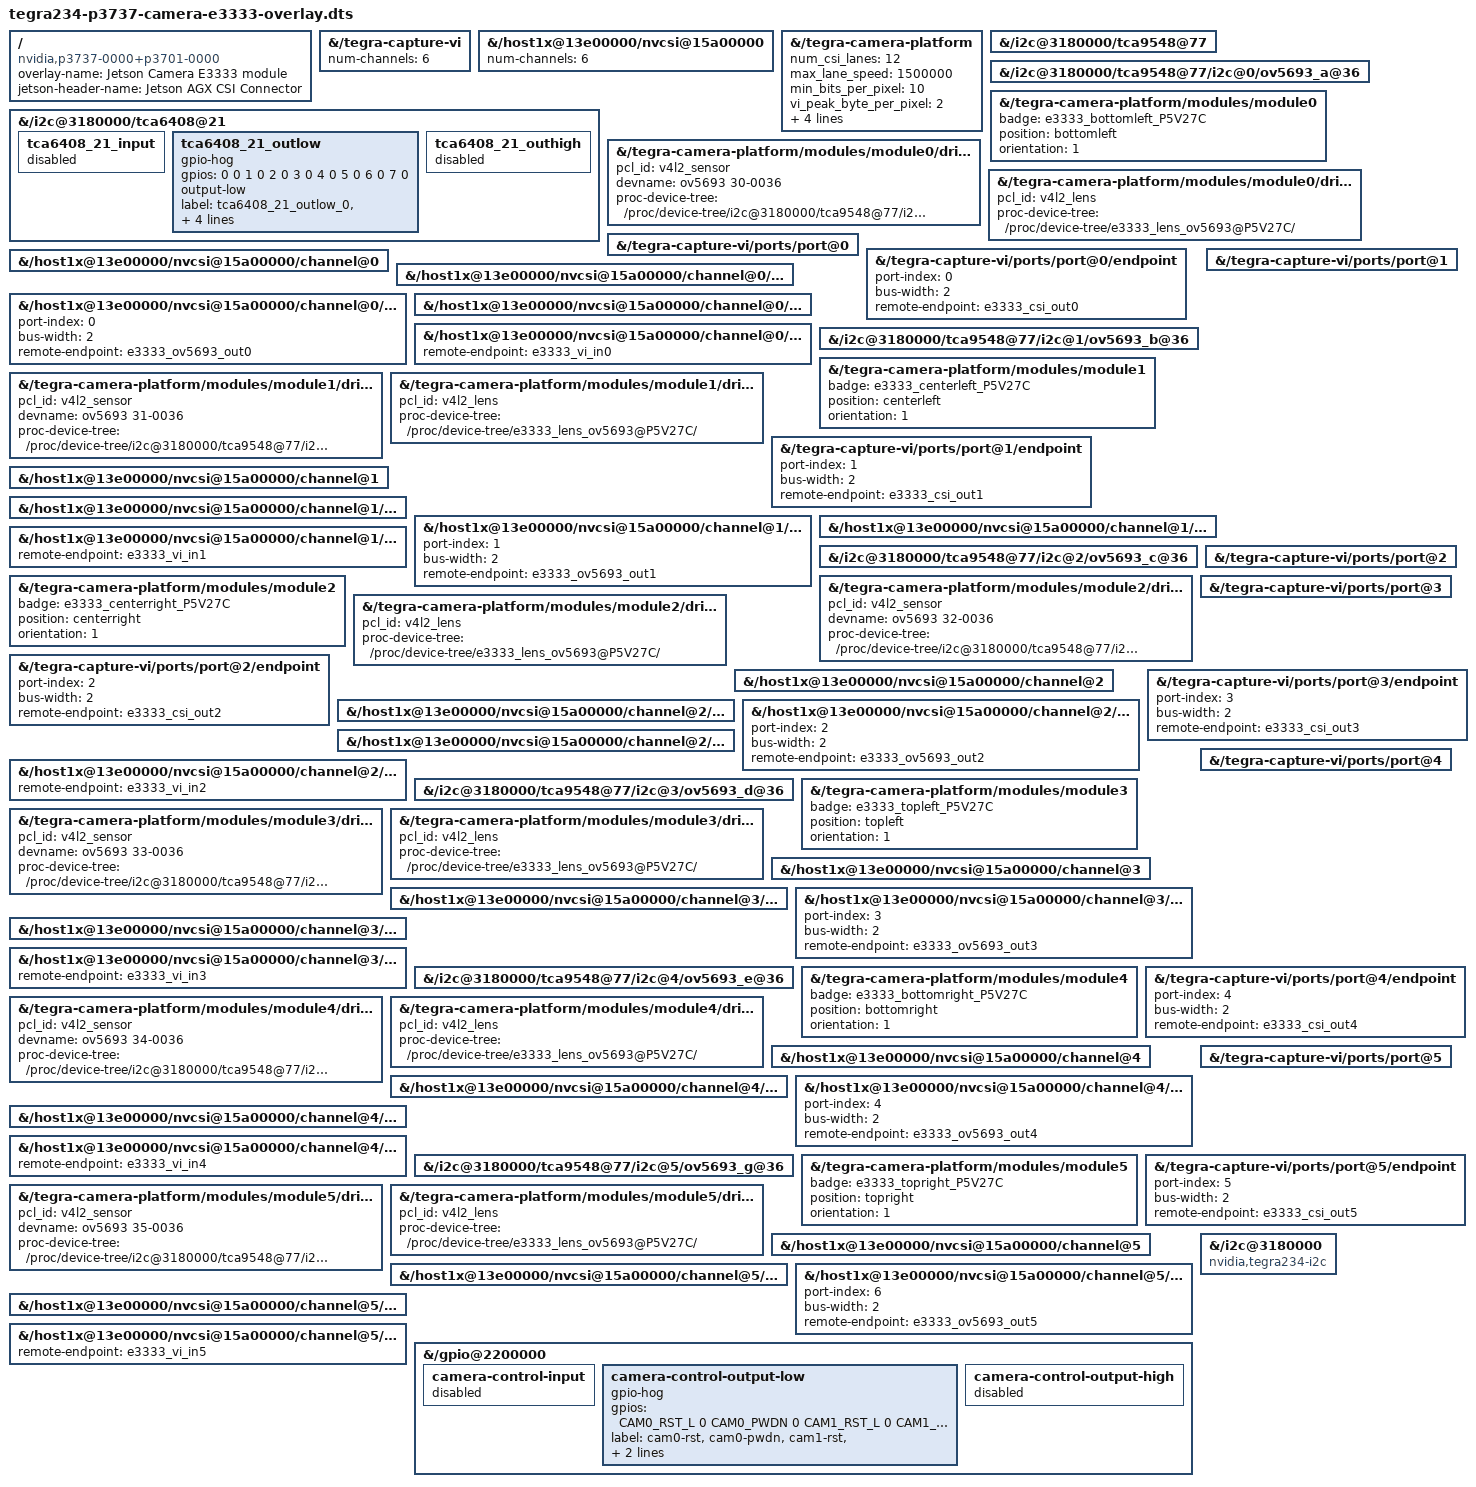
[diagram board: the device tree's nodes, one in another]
// SPDX-License-Identifier: GPL-2.0-only
/*
 * Jetson Device-tree overlay for Camera E3333 module on t23x platforms
 *
 * Copyright (c) 2022-2023 NVIDIA CORPORATION. All rights reserved.
 *
 */


/dts-v1/;
/plugin/;

#include <dt-bindings/gpio/tegra234-gpio.h>

#define CAM0_RST_L      TEGRA234_MAIN_GPIO(H, 3)
#define CAM0_PWDN       TEGRA234_MAIN_GPIO(H, 6)
#define CAM1_RST_L      TEGRA234_MAIN_GPIO(AC, 1)
#define CAM1_PWDN       TEGRA234_MAIN_GPIO(AC, 0)

/ {
	overlay-name = "Jetson Camera E3333 module";
	jetson-header-name = "Jetson AGX CSI Connector";
	compatible = "nvidia,p3737-0000+p3701-0000" , "nvidia,p3737-0000+p3701-0004", "nvidia,p3737-0000+p3701-0005", "nvidia,p3737-0000+p3701-0008";

	/* Use either odm-data or eeprom-ids for sensor detection */

	/* E3333 camera board */
	/* VI number of channels */
	fragment@0 {
		/// target = <&capture_vi_base>;
		target-path = "/tegra-capture-vi";
		board_config {
			// odm-data = "enable-3333-ov5693";
			ids = "3333-*";
			sw-modules = "kernel";
		};
		__overlay__ {
			num-channels=<6>;
		};
	};
	/* CSI number of channels */
	fragment@1 {
		/// target = <&csi_base>;
		target-path = "/host1x@13e00000/nvcsi@15a00000";
		board_config {
			// odm-data = "enable-3333-ov5693";
			ids = "3333-*";
			sw-modules = "kernel";
		};
		__overlay__ {
			num-channels=<6>;
		};
	};
	/* tegra-camera-platform settings */
	fragment@2 {
		/// target = <&tcp>;
		target-path = "/tegra-camera-platform";
		board_config {
			// odm-data = "enable-3333-ov5693";
			ids = "3333-*";
			sw-modules = "kernel";
		};
		__overlay__ {
			num_csi_lanes = <12>;
			max_lane_speed = <1500000>;
			min_bits_per_pixel = <10>;
			vi_peak_byte_per_pixel = <2>;
			vi_bw_margin_pct = <25>;
			max_pixel_rate = <200000>;
			isp_peak_byte_per_pixel = <5>;
			isp_bw_margin_pct = <25>;
		};
	};
	/* TCA6408 */
	fragment@3 {
		/// target = <&tca6408_21>;
		target-path = "/i2c@3180000/tca6408@21";
		board_config {
			// odm-data = "enable-3333-ov5693";
			ids = "3333-*";
			sw-modules = "kernel";
		};
		__overlay__ {
			status = "okay";
		};
	};
	/* TCA9548 */
	fragment@4 {
		/// target = <&tca9548_77>;
		target-path = "/i2c@3180000/tca9548@77";
		board_config {
			// odm-data = "enable-3333-ov5693";
			ids = "3333-*";
			sw-modules = "kernel";
		};
		__overlay__ {
			status = "okay";
		};
	};
	/* Camera 0: Module */
	fragment@5 {
		/// target = <&e3333_cam0>;
		target-path = "/i2c@3180000/tca9548@77/i2c@0/ov5693_a@36";
		board_config {
			// odm-data = "enable-3333-ov5693";
			ids = "3333-*";
			sw-modules = "kernel";
		};
		__overlay__ {
			status = "okay";
		};
	};
	fragment@6 {
		/// target = <&cam_module0>;
		target-path = "/tegra-camera-platform/modules/module0";
		board_config {
			// odm-data = "enable-3333-ov5693";
			ids = "3333-*";
			sw-modules = "kernel";
		};
		__overlay__ {
			status = "okay";
			badge = "e3333_bottomleft_P5V27C";
			position = "bottomleft";
			orientation = "1";
		};
	};
	fragment@7 {
		/// target = <&cam_module0_drivernode0>;
		target-path = "/tegra-camera-platform/modules/module0/drivernode0";
		board_config {
			// odm-data = "enable-3333-ov5693";
			ids = "3333-*";
			sw-modules = "kernel";
		};
		__overlay__ {
			status = "okay";
			pcl_id = "v4l2_sensor";
			devname = "ov5693 30-0036";
			proc-device-tree = "/proc/device-tree/i2c@3180000/tca9548@77/i2c@0/ov5693_a@36";
		};
	};
	fragment@8 {
		/// target = <&cam_module0_drivernode1>;
		target-path = "/tegra-camera-platform/modules/module0/drivernode1";
		board_config {
			// odm-data = "enable-3333-ov5693";
			ids = "3333-*";
			sw-modules = "kernel";
		};
		__overlay__ {
			status = "okay";
			pcl_id = "v4l2_lens";
			proc-device-tree = "/proc/device-tree/e3333_lens_ov5693@P5V27C/";
		};
	};
	/* Camera 0: VI */
	fragment@9 {
		/// target = <&vi_port0>;
		target-path = "/tegra-capture-vi/ports/port@0";
		board_config {
			// odm-data = "enable-3333-ov5693";
			ids = "3333-*";
			sw-modules = "kernel";
		};
		__overlay__ {
			status = "okay";
		};
	};
	fragment@10 {
		/// target = <&e3333_vi_in0>;
		target-path = "/tegra-capture-vi/ports/port@0/endpoint";
		board_config {
			// odm-data = "enable-3333-ov5693";
			ids = "3333-*";
			sw-modules = "kernel";
		};
		__overlay__ {
			status = "okay";
			port-index = <0>;
			bus-width = <2>;
			remote-endpoint = <&e3333_csi_out0>;
			/// remote-endpoint = "/host1x@13e00000/nvcsi@15a00000/channel@0/ports/port@1/endpoint@1";
		};
	};
	/* Camera 0: CSI */
	fragment@11 {
		/// target = <&csi_chan0>;
		target-path = "/host1x@13e00000/nvcsi@15a00000/channel@0";
		board_config {
			// odm-data = "enable-3333-ov5693";
			ids = "3333-*";
			sw-modules = "kernel";
		};
		__overlay__ {
			status = "okay";
		};
	};
	fragment@12 {
		/// target = <&csi_chan0_port0>;
		target-path = "/host1x@13e00000/nvcsi@15a00000/channel@0/ports/port@0";
		board_config {
			// odm-data = "enable-3333-ov5693";
			ids = "3333-*";
			sw-modules = "kernel";
		};
		__overlay__ {
			status = "okay";
		};
	};
	fragment@13 {
		/// target = <&e3333_csi_in0>;
		target-path = "/host1x@13e00000/nvcsi@15a00000/channel@0/ports/port@0/endpoint@0";
		board_config {
			// odm-data = "enable-3333-ov5693";
			ids = "3333-*";
			sw-modules = "kernel";
		};
		__overlay__ {
			status = "okay";
			port-index = <0>;
			bus-width = <2>;
			remote-endpoint = <&e3333_ov5693_out0>;
			/// remote-endpoint = "/i2c@3180000/tca9548@77/i2c@0/ov5693_a@36/ports/port@0/endpoint";
		};
	};
	fragment@14 {
		/// target = <&csi_chan0_port1>;
		target-path = "/host1x@13e00000/nvcsi@15a00000/channel@0/ports/port@1";
		board_config {
			// odm-data = "enable-3333-ov5693";
			ids = "3333-*";
			sw-modules = "kernel";
		};
		__overlay__ {
			status = "okay";
		};
	};
	fragment@15 {
		/// target = <&e3333_csi_out0>;
		target-path = "/host1x@13e00000/nvcsi@15a00000/channel@0/ports/port@1/endpoint@1";
		board_config {
			// odm-data = "enable-3333-ov5693";
			ids = "3333-*";
			sw-modules = "kernel";
		};
		__overlay__ {
			status = "okay";
			remote-endpoint = <&e3333_vi_in0>;
			/// remote-endpoint = "/tegra-capture-vi/ports/port@0/endpoint";
		};
	};
	/* Camera 1: Module */
	fragment@16 {
		/// target = <&e3333_cam1>;
		target-path = "/i2c@3180000/tca9548@77/i2c@1/ov5693_b@36";
		board_config {
			// odm-data = "enable-3333-ov5693";
			ids = "3333-*";
			sw-modules = "kernel";
		};
		__overlay__ {
			status = "okay";
		};
	};
	fragment@17 {
		/// target = <&cam_module1>;
		target-path = "/tegra-camera-platform/modules/module1";
		board_config {
			// odm-data = "enable-3333-ov5693";
			ids = "3333-*";
			sw-modules = "kernel";
		};
		__overlay__ {
			status = "okay";
			badge = "e3333_centerleft_P5V27C";
			position = "centerleft";
			orientation = "1";
		};
	};
	fragment@18 {
		/// target = <&cam_module1_drivernode0>;
		target-path = "/tegra-camera-platform/modules/module1/drivernode0";
		board_config {
			// odm-data = "enable-3333-ov5693";
			ids = "3333-*";
			sw-modules = "kernel";
		};
		__overlay__ {
			status = "okay";
			pcl_id = "v4l2_sensor";
			devname = "ov5693 31-0036";
			proc-device-tree = "/proc/device-tree/i2c@3180000/tca9548@77/i2c@1/ov5693_b@36";
		};
	};
	fragment@19 {
		/// target = <&cam_module1_drivernode1>;
		target-path = "/tegra-camera-platform/modules/module1/drivernode1";
		board_config {
			// odm-data = "enable-3333-ov5693";
			ids = "3333-*";
			sw-modules = "kernel";
		};
		__overlay__ {
			status = "okay";
			pcl_id = "v4l2_lens";
			proc-device-tree = "/proc/device-tree/e3333_lens_ov5693@P5V27C/";
		};
	};
	/* Camera 1: VI */
	fragment@20 {
		/// target = <&vi_port1>;
		target-path = "/tegra-capture-vi/ports/port@1";
		board_config {
			// odm-data = "enable-3333-ov5693";
			ids = "3333-*";
			sw-modules = "kernel";
		};
		__overlay__ {
			status = "okay";
		};
	};
	fragment@21 {
		/// target = <&e3333_vi_in1>;
		target-path = "/tegra-capture-vi/ports/port@1/endpoint";
		board_config {
			// odm-data = "enable-3333-ov5693";
			ids = "3333-*";
			sw-modules = "kernel";
		};
		__overlay__ {
			status = "okay";
			port-index = <1>;
			bus-width = <2>;
			remote-endpoint = <&e3333_csi_out1>;
			/// remote-endpoint = "/host1x@13e00000/nvcsi@15a00000/channel@1/ports/port@1/endpoint@3";
		};
	};
	/* Camera 1: CSI */
	fragment@22 {
		/// target = <&csi_chan1>;
		target-path = "/host1x@13e00000/nvcsi@15a00000/channel@1";
		board_config {
			// odm-data = "enable-3333-ov5693";
			ids = "3333-*";
			sw-modules = "kernel";
		};
		__overlay__ {
			status = "okay";
		};
	};
	fragment@23 {
		/// target = <&csi_chan1_port0>;
		target-path = "/host1x@13e00000/nvcsi@15a00000/channel@1/ports/port@0";
		board_config {
			// odm-data = "enable-3333-ov5693";
			ids = "3333-*";
			sw-modules = "kernel";
		};
		__overlay__ {
			status = "okay";
		};
	};
	fragment@24 {
		/// target = <&e3333_csi_in1>;
		target-path = "/host1x@13e00000/nvcsi@15a00000/channel@1/ports/port@0/endpoint@2";
		board_config {
			// odm-data = "enable-3333-ov5693";
			ids = "3333-*";
			sw-modules = "kernel";
		};
		__overlay__ {
			status = "okay";
			port-index = <1>;
			bus-width = <2>;
			remote-endpoint = <&e3333_ov5693_out1>;
			/// remote-endpoint = "/i2c@3180000/tca9548@77/i2c@1/ov5693_b@36/ports/port@0/endpoint";
		};
	};
	fragment@25 {
		/// target = <&csi_chan1_port1>;
		target-path = "/host1x@13e00000/nvcsi@15a00000/channel@1/ports/port@1";
		board_config {
			// odm-data = "enable-3333-ov5693";
			ids = "3333-*";
			sw-modules = "kernel";
		};
		__overlay__ {
			status = "okay";
		};
	};
	fragment@26 {
		/// target = <&e3333_csi_out1>;
		target-path = "/host1x@13e00000/nvcsi@15a00000/channel@1/ports/port@1/endpoint@3";
		board_config {
			// odm-data = "enable-3333-ov5693";
			ids = "3333-*";
			sw-modules = "kernel";
		};
		__overlay__ {
			status = "okay";
			remote-endpoint = <&e3333_vi_in1>;
			/// remote-endpoint = "/tegra-capture-vi/ports/port@1/endpoint";
		};
	};
	/* Camera 2: Module */
	fragment@27 {
		/// target = <&e3333_cam2>;
		target-path = "/i2c@3180000/tca9548@77/i2c@2/ov5693_c@36";
		board_config {
			// odm-data = "enable-3333-ov5693";
			ids = "3333-*";
			sw-modules = "kernel";
		};
		__overlay__ {
			status = "okay";
		};
	};
	fragment@28 {
		/// target = <&cam_module2>;
		target-path = "/tegra-camera-platform/modules/module2";
		board_config {
			// odm-data = "enable-3333-ov5693";
			ids = "3333-*";
			sw-modules = "kernel";
		};
		__overlay__ {
			status = "okay";
			badge = "e3333_centerright_P5V27C";
			position = "centerright";
			orientation = "1";
		};
	};
	fragment@29 {
		/// target = <&cam_module2_drivernode0>;
		target-path = "/tegra-camera-platform/modules/module2/drivernode0";
		board_config {
			// odm-data = "enable-3333-ov5693";
			ids = "3333-*";
			sw-modules = "kernel";
		};
		__overlay__ {
			status = "okay";
			pcl_id = "v4l2_sensor";
			devname = "ov5693 32-0036";
			proc-device-tree = "/proc/device-tree/i2c@3180000/tca9548@77/i2c@2/ov5693_c@36";
		};
	};
	fragment@30 {
		/// target = <&cam_module2_drivernode1>;
		target-path = "/tegra-camera-platform/modules/module2/drivernode1";
		board_config {
			// odm-data = "enable-3333-ov5693";
			ids = "3333-*";
			sw-modules = "kernel";
		};
		__overlay__ {
			status = "okay";
			pcl_id = "v4l2_lens";
			proc-device-tree = "/proc/device-tree/e3333_lens_ov5693@P5V27C/";
		};
	};
	/* Camera 2: VI */
	fragment@31 {
		/// target = <&vi_port2>;
		target-path = "/tegra-capture-vi/ports/port@2";
		board_config {
			// odm-data = "enable-3333-ov5693";
			ids = "3333-*";
			sw-modules = "kernel";
		};
		__overlay__ {
			status = "okay";
		};
	};
	fragment@32 {
		/// target = <&e3333_vi_in2>;
		target-path = "/tegra-capture-vi/ports/port@2/endpoint";
		board_config {
			// odm-data = "enable-3333-ov5693";
			ids = "3333-*";
			sw-modules = "kernel";
		};
		__overlay__ {
			status = "okay";
			port-index = <2>;
			bus-width = <2>;
			remote-endpoint = <&e3333_csi_out2>;
			/// remote-endpoint = "/host1x@13e00000/nvcsi@15a00000/channel@2/ports/port@1/endpoint@5";
		};
	};
	/* Camera 2: CSI */
	fragment@33 {
		/// target = <&csi_chan2>;
		target-path = "/host1x@13e00000/nvcsi@15a00000/channel@2";
		board_config {
			// odm-data = "enable-3333-ov5693";
			ids = "3333-*";
			sw-modules = "kernel";
		};
		__overlay__ {
			status = "okay";
		};
	};
	fragment@34 {
		/// target = <&csi_chan2_port0>;
		target-path = "/host1x@13e00000/nvcsi@15a00000/channel@2/ports/port@0";
		board_config {
			// odm-data = "enable-3333-ov5693";
			ids = "3333-*";
			sw-modules = "kernel";
		};
		__overlay__ {
			status = "okay";
		};
	};
	fragment@35 {
		/// target = <&e3333_csi_in2>;
		target-path = "/host1x@13e00000/nvcsi@15a00000/channel@2/ports/port@0/endpoint@4";
		board_config {
			// odm-data = "enable-3333-ov5693";
			ids = "3333-*";
			sw-modules = "kernel";
		};
		__overlay__ {
			status = "okay";
			port-index = <2>;
			bus-width = <2>;
			remote-endpoint = <&e3333_ov5693_out2>;
			/// remote-endpoint = "/i2c@3180000/tca9548@77/i2c@2/ov5693_c@36/ports/port@0/endpoint";
		};
	};
	fragment@36 {
		/// target = <&csi_chan2_port1>;
		target-path = "/host1x@13e00000/nvcsi@15a00000/channel@2/ports/port@1";
		board_config {
			// odm-data = "enable-3333-ov5693";
			ids = "3333-*";
			sw-modules = "kernel";
		};
		__overlay__ {
			status = "okay";
		};
	};
	fragment@37 {
		/// target = <&e3333_csi_out2>;
		target-path = "/host1x@13e00000/nvcsi@15a00000/channel@2/ports/port@1/endpoint@5";
		board_config {
			// odm-data = "enable-3333-ov5693";
			ids = "3333-*";
			sw-modules = "kernel";
		};
		__overlay__ {
			status = "okay";
			remote-endpoint = <&e3333_vi_in2>;
			/// remote-endpoint = "/tegra-capture-vi/ports/port@2/endpoint";
		};
	};
	/* Camera 3: Module */
	fragment@38 {
		/// target = <&e3333_cam3>;
		target-path = "/i2c@3180000/tca9548@77/i2c@3/ov5693_d@36";
		board_config {
			// odm-data = "enable-3333-ov5693";
			ids = "3333-*";
			sw-modules = "kernel";
		};
		__overlay__ {
			status = "okay";
		};
	};
	fragment@39 {
		/// target = <&cam_module3>;
		target-path = "/tegra-camera-platform/modules/module3";
		board_config {
			// odm-data = "enable-3333-ov5693";
			ids = "3333-*";
			sw-modules = "kernel";
		};
		__overlay__ {
			status = "okay";
			badge = "e3333_topleft_P5V27C";
			position = "topleft";
			orientation = "1";
		};
	};
	fragment@40 {
		/// target = <&cam_module3_drivernode0>;
		target-path = "/tegra-camera-platform/modules/module3/drivernode0";
		board_config {
			// odm-data = "enable-3333-ov5693";
			ids = "3333-*";
			sw-modules = "kernel";
		};
		__overlay__ {
			status = "okay";
			pcl_id = "v4l2_sensor";
			devname = "ov5693 33-0036";
			proc-device-tree = "/proc/device-tree/i2c@3180000/tca9548@77/i2c@3/ov5693_d@36";
		};
	};
	fragment@41 {
		/// target = <&cam_module3_drivernode1>;
		target-path = "/tegra-camera-platform/modules/module3/drivernode1";
		board_config {
			// odm-data = "enable-3333-ov5693";
			ids = "3333-*";
			sw-modules = "kernel";
		};
		__overlay__ {
			status = "okay";
			pcl_id = "v4l2_lens";
			proc-device-tree = "/proc/device-tree/e3333_lens_ov5693@P5V27C/";
		};
	};
	/* Camera 3: VI */
	fragment@42 {
		/// target = <&vi_port3>;
		target-path = "/tegra-capture-vi/ports/port@3";
		board_config {
			// odm-data = "enable-3333-ov5693";
			ids = "3333-*";
			sw-modules = "kernel";
		};
		__overlay__ {
			status = "okay";
		};
	};
	fragment@43 {
		/// target = <&e3333_vi_in3>;
		target-path = "/tegra-capture-vi/ports/port@3/endpoint";
		board_config {
			// odm-data = "enable-3333-ov5693";
			ids = "3333-*";
			sw-modules = "kernel";
		};
		__overlay__ {
			status = "okay";
			port-index = <3>;
			bus-width = <2>;
			remote-endpoint = <&e3333_csi_out3>;
			/// remote-endpoint = "/host1x@13e00000/nvcsi@15a00000/channel@3/ports/port@1/endpoint@7";
		};
	};
	/* Camera 3: CSI */
	fragment@44 {
		/// target = <&csi_chan3>;
		target-path = "/host1x@13e00000/nvcsi@15a00000/channel@3";
		board_config {
			// odm-data = "enable-3333-ov5693";
			ids = "3333-*";
			sw-modules = "kernel";
		};
		__overlay__ {
			status = "okay";
		};
	};
	fragment@45 {
		/// target = <&csi_chan3_port0>;
		target-path = "/host1x@13e00000/nvcsi@15a00000/channel@3/ports/port@0";
		board_config {
			// odm-data = "enable-3333-ov5693";
			ids = "3333-*";
			sw-modules = "kernel";
		};
		__overlay__ {
			status = "okay";
		};
	};
	fragment@46 {
		/// target = <&e3333_csi_in3>;
		target-path = "/host1x@13e00000/nvcsi@15a00000/channel@3/ports/port@0/endpoint@6";
		board_config {
			// odm-data = "enable-3333-ov5693";
			ids = "3333-*";
			sw-modules = "kernel";
		};
		__overlay__ {
			status = "okay";
			port-index = <3>;
			bus-width = <2>;
			remote-endpoint = <&e3333_ov5693_out3>;
			/// remote-endpoint = "/i2c@3180000/tca9548@77/i2c@3/ov5693_d@36/ports/port@0/endpoint";
		};
	};
	fragment@47 {
		/// target = <&csi_chan3_port1>;
		target-path = "/host1x@13e00000/nvcsi@15a00000/channel@3/ports/port@1";
		board_config {
			// odm-data = "enable-3333-ov5693";
			ids = "3333-*";
			sw-modules = "kernel";
		};
		__overlay__ {
			status = "okay";
		};
	};
	fragment@48 {
		/// target = <&e3333_csi_out3>;
		target-path = "/host1x@13e00000/nvcsi@15a00000/channel@3/ports/port@1/endpoint@7";
		board_config {
			// odm-data = "enable-3333-ov5693";
			ids = "3333-*";
			sw-modules = "kernel";
		};
		__overlay__ {
			status = "okay";
			remote-endpoint = <&e3333_vi_in3>;
			/// remote-endpoint = "/tegra-capture-vi/ports/port@3/endpoint";
		};
	};
	/* Camera 4: Module */
	fragment@49 {
		/// target = <&e3333_cam4>;
		target-path = "/i2c@3180000/tca9548@77/i2c@4/ov5693_e@36";
		board_config {
			// odm-data = "enable-3333-ov5693";
			ids = "3333-*";
			sw-modules = "kernel";
		};
		__overlay__ {
			status = "okay";
		};
	};
	fragment@50 {
		/// target = <&cam_module4>;
		target-path = "/tegra-camera-platform/modules/module4";
		board_config {
			// odm-data = "enable-3333-ov5693";
			ids = "3333-*";
			sw-modules = "kernel";
		};
		__overlay__ {
			status = "okay";
			badge = "e3333_bottomright_P5V27C";
			position = "bottomright";
			orientation = "1";
		};
	};
	fragment@51 {
		/// target = <&cam_module4_drivernode0>;
		target-path = "/tegra-camera-platform/modules/module4/drivernode0";
		board_config {
			// odm-data = "enable-3333-ov5693";
			ids = "3333-*";
			sw-modules = "kernel";
		};
		__overlay__ {
			status = "okay";
			pcl_id = "v4l2_sensor";
			devname = "ov5693 34-0036";
			proc-device-tree = "/proc/device-tree/i2c@3180000/tca9548@77/i2c@4/ov5693_e@36";
		};
	};
	fragment@52 {
		/// target = <&cam_module4_drivernode1>;
		target-path = "/tegra-camera-platform/modules/module4/drivernode1";
		board_config {
			// odm-data = "enable-3333-ov5693";
			ids = "3333-*";
			sw-modules = "kernel";
		};
		__overlay__ {
			status = "okay";
			pcl_id = "v4l2_lens";
			proc-device-tree = "/proc/device-tree/e3333_lens_ov5693@P5V27C/";
		};
	};
	/* Camera 4: VI */
	fragment@53 {
		/// target = <&vi_port4>;
		target-path = "/tegra-capture-vi/ports/port@4";
		board_config {
			// odm-data = "enable-3333-ov5693";
			ids = "3333-*";
			sw-modules = "kernel";
		};
		__overlay__ {
			status = "okay";
		};
	};
	fragment@54 {
		/// target = <&e3333_vi_in4>;
		target-path = "/tegra-capture-vi/ports/port@4/endpoint";
		board_config {
			// odm-data = "enable-3333-ov5693";
			ids = "3333-*";
			sw-modules = "kernel";
		};
		__overlay__ {
			status = "okay";
			port-index = <4>;
			bus-width = <2>;
			remote-endpoint = <&e3333_csi_out4>;
			/// remote-endpoint = "/host1x@13e00000/nvcsi@15a00000/channel@4/ports/port@1/endpoint@9";
		};
	};
	/* Camera 4: CSI */
	fragment@55 {
		/// target = <&csi_chan4>;
		target-path = "/host1x@13e00000/nvcsi@15a00000/channel@4";
		board_config {
			// odm-data = "enable-3333-ov5693";
			ids = "3333-*";
			sw-modules = "kernel";
		};
		__overlay__ {
			status = "okay";
		};
	};
	fragment@56 {
		/// target = <&csi_chan4_port0>;
		target-path = "/host1x@13e00000/nvcsi@15a00000/channel@4/ports/port@0";
		board_config {
			// odm-data = "enable-3333-ov5693";
			ids = "3333-*";
			sw-modules = "kernel";
		};
		__overlay__ {
			status = "okay";
		};
	};
	fragment@57 {
		/// target = <&e3333_csi_in4>;
		target-path = "/host1x@13e00000/nvcsi@15a00000/channel@4/ports/port@0/endpoint@8";
		board_config {
			// odm-data = "enable-3333-ov5693";
			ids = "3333-*";
			sw-modules = "kernel";
		};
		__overlay__ {
			status = "okay";
			port-index = <4>;
			bus-width = <2>;
			remote-endpoint = <&e3333_ov5693_out4>;
			/// remote-endpoint = "/i2c@3180000/tca9548@77/i2c@4/ov5693_e@36/ports/port@0/endpoint";
		};
	};
	fragment@58 {
		/// target = <&csi_chan4_port1>;
		target-path = "/host1x@13e00000/nvcsi@15a00000/channel@4/ports/port@1";
		board_config {
			// odm-data = "enable-3333-ov5693";
			ids = "3333-*";
			sw-modules = "kernel";
		};
		__overlay__ {
			status = "okay";
		};
	};
	fragment@59 {
		/// target = <&e3333_csi_out4>;
		target-path = "/host1x@13e00000/nvcsi@15a00000/channel@4/ports/port@1/endpoint@9";
		board_config {
			// odm-data = "enable-3333-ov5693";
			ids = "3333-*";
			sw-modules = "kernel";
		};
		__overlay__ {
			status = "okay";
			remote-endpoint = <&e3333_vi_in4>;
			/// remote-endpoint = "/tegra-capture-vi/ports/port@4/endpoint";
		};
	};
	/* Camera 5: Module */
	fragment@60 {
		/// target = <&e3333_cam5>;
		target-path = "/i2c@3180000/tca9548@77/i2c@5/ov5693_g@36";
		board_config {
			// odm-data = "enable-3333-ov5693";
			ids = "3333-*";
			sw-modules = "kernel";
		};
		__overlay__ {
			status = "okay";
		};
	};
	fragment@61 {
		/// target = <&cam_module5>;
		target-path = "/tegra-camera-platform/modules/module5";
		board_config {
			// odm-data = "enable-3333-ov5693";
			ids = "3333-*";
			sw-modules = "kernel";
		};
		__overlay__ {
			status = "okay";
			badge = "e3333_topright_P5V27C";
			position = "topright";
			orientation = "1";
		};
	};
	fragment@62 {
		/// target = <&cam_module5_drivernode0>;
		target-path = "/tegra-camera-platform/modules/module5/drivernode0";
		board_config {
			// odm-data = "enable-3333-ov5693";
			ids = "3333-*";
			sw-modules = "kernel";
		};
		__overlay__ {
			status = "okay";
			pcl_id = "v4l2_sensor";
			devname = "ov5693 35-0036";
			proc-device-tree = "/proc/device-tree/i2c@3180000/tca9548@77/i2c@5/ov5693_g@36";
		};
	};
	fragment@63 {
		/// target = <&cam_module5_drivernode1>;
		target-path = "/tegra-camera-platform/modules/module5/drivernode1";
		board_config {
			// odm-data = "enable-3333-ov5693";
			ids = "3333-*";
			sw-modules = "kernel";
		};
		__overlay__ {
			status = "okay";
			pcl_id = "v4l2_lens";
			proc-device-tree = "/proc/device-tree/e3333_lens_ov5693@P5V27C/";
		};
	};
	/* Camera 5: VI */
	fragment@64 {
		/// target = <&vi_port5>;
		target-path = "/tegra-capture-vi/ports/port@5";
		board_config {
			// odm-data = "enable-3333-ov5693";
			ids = "3333-*";
			sw-modules = "kernel";
		};
		__overlay__ {
			status = "okay";
		};
	};
	fragment@65 {
		/// target = <&e3333_vi_in5>;
		target-path = "/tegra-capture-vi/ports/port@5/endpoint";
		board_config {
			// odm-data = "enable-3333-ov5693";
			ids = "3333-*";
			sw-modules = "kernel";
		};
		__overlay__ {
			status = "okay";
			port-index = <5>;
			bus-width = <2>;
			remote-endpoint = <&e3333_csi_out5>;
			/// remote-endpoint = "/host1x@13e00000/nvcsi@15a00000/channel@5/ports/port@1/endpoint@11";
		};
	};
	/* Camera 5: CSI */
	fragment@66 {
		/// target = <&csi_chan5>;
		target-path = "/host1x@13e00000/nvcsi@15a00000/channel@5";
		board_config {
			// odm-data = "enable-3333-ov5693";
			ids = "3333-*";
			sw-modules = "kernel";
		};
		__overlay__ {
			status = "okay";
		};
	};
	fragment@67 {
		/// target = <&csi_chan5_port0>;
		target-path = "/host1x@13e00000/nvcsi@15a00000/channel@5/ports/port@0";
		board_config {
			// odm-data = "enable-3333-ov5693";
			ids = "3333-*";
			sw-modules = "kernel";
		};
		__overlay__ {
			status = "okay";
		};
	};
	fragment@68 {
		/// target = <&e3333_csi_in5>;
		target-path = "/host1x@13e00000/nvcsi@15a00000/channel@5/ports/port@0/endpoint@10";
		board_config {
			// odm-data = "enable-3333-ov5693";
			ids = "3333-*";
			sw-modules = "kernel";
		};
		__overlay__ {
			status = "okay";
			port-index = <6>;
			bus-width = <2>;
			remote-endpoint = <&e3333_ov5693_out5>;
			/// remote-endpoint = "/i2c@3180000/tca9548@77/i2c@5/ov5693_g@36/ports/port@0/endpoint";
		};
	};
	fragment@69 {
		/// target = <&csi_chan5_port1>;
		target-path = "/host1x@13e00000/nvcsi@15a00000/channel@5/ports/port@1";
		board_config {
			// odm-data = "enable-3333-ov5693";
			ids = "3333-*";
			sw-modules = "kernel";
		};
		__overlay__ {
			status = "okay";
		};
	};
	fragment@70 {
		/// target = <&e3333_csi_out5>;
		target-path = "/host1x@13e00000/nvcsi@15a00000/channel@5/ports/port@1/endpoint@11";
		board_config {
			// odm-data = "enable-3333-ov5693";
			ids = "3333-*";
			sw-modules = "kernel";
		};
		__overlay__ {
			status = "okay";
			remote-endpoint = <&e3333_vi_in5>;
			/// remote-endpoint = "/tegra-capture-vi/ports/port@5/endpoint";
		};
	};
	/* GPIO */
	fragment@71 {
		/// target = <&{/gpio@2200000}>;
		target-path = "/gpio@2200000";
		board_config {
			// odm-data = "enable-3333-ov5693";
			ids = "3333-*";
			sw-modules = "kernel";
		};
		__overlay__ {
			camera-control-input {
				status = "disabled";
			};
			camera-control-output-low {
				gpio-hog;
				gpios = <CAM0_RST_L 0 CAM0_PWDN 0
					 CAM1_RST_L 0 CAM1_PWDN 0>;
				label = "cam0-rst", "cam0-pwdn",
					"cam1-rst", "cam1-pwdn";
				output-low;
				status = "okay";
			};
			camera-control-output-high {
				status = "disabled";
			};
		};
	};
	/* TCA6408 default */
	fragment@72 {
		/// target = <&tca6408_21>;
		target-path = "/i2c@3180000/tca6408@21";
		board_config {
			// odm-data = "enable-3333-ov5693";
			ids = "3333-*";
			sw-modules = "kernel";
		};
		__overlay__ {
			tca6408_21_input {
				status = "disabled";
			};
			tca6408_21_outlow {
				gpio-hog;
				gpios = <0 0 1 0 2 0 3 0 4 0
					 5 0 6 0 7 0>;
				output-low;
				label = "tca6408_21_outlow_0",
					"tca6408_21_outlow_1",
					"tca6408_21_outlow_2",
					"tca6408_21_outlow_3",
					"tca6408_21_outlow_4",
					"tca6408_21_outlow_5",
					"tca6408_21_outlow_6",
					"tca6408_21_outlow_7";
				status = "okay";
			};
			tca6408_21_outhigh {
				status = "disabled";
			};
		};
	};
	/* I2C default */
	fragment@73 {
		/// target = <&cam_i2c>;
		target-path = "/i2c@3180000";
		board_config {
			// odm-data = "enable-3333-ov5693";
			ids = "3333-*";
			sw-modules = "kernel";
		};
		__overlay__ {
			compatible = "nvidia,tegra234-i2c";
		};
	};
};
